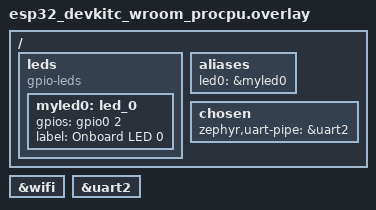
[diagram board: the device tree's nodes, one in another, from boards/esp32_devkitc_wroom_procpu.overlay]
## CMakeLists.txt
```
cmake_minimum_required(VERSION 3.13.1)
message("WORKSPACE_BASE = $ENV{WORKSPACE_BASE}")
message("ZEPHYR_BASE = $ENV{ZEPHYR_BASE}")
message("ZEPHYR_SDK_INSTALL_DIR = $ENV{ZEPHYR_SDK_INSTALL_DIR}")
message("ZEPHYR_TOOLCHAIN_VARIANT = $ENV{ZEPHYR_TOOLCHAIN_VARIANT}")

set(CONFIG_OUTPUT_DISASSEMBLY y CACHE INTERNAL "")
set(CONFIG_OUTPUT_DISASSEMBLY_WITH_SOURCE y CACHE INTERNAL "")

list(APPEND EXTRA_CONF_FILE
    ${CMAKE_CURRENT_SOURCE_DIR}/conf/kernel.conf
    ${CMAKE_CURRENT_SOURCE_DIR}/conf/net.conf
    ${CMAKE_CURRENT_SOURCE_DIR}/conf/modules.conf
    ${CMAKE_CURRENT_SOURCE_DIR}/conf/rpc.conf
    ${CMAKE_CURRENT_SOURCE_DIR}/conf/tracing.conf
    ${CMAKE_CURRENT_SOURCE_DIR}/conf/tracemodule.conf
)

# Which networking fragment to apply. Declare the type with
# CONFIG_APP_NET_TYPE_<X>=y in boards/<board>.conf (or prj.conf); the helper reads
# that declaration here, because CONFIG_* are not CMake variables until
# find_package(Zephyr) below has run Kconfig -- by which point EXTRA_CONF_FILE is
# already consumed. See the header of app_net_type.cmake.
#
# The "wifi" fallback must match the 'choice APP_NET_TYPE' default in Kconfig.
include($ENV{WORKSPACE_BASE}/common/scripts/cmake/app_net_type.cmake)
app_net_type_resolve(APP_NET_TYPE wifi)

if (APP_NET_TYPE STREQUAL "wifi")
    list(APPEND EXTRA_CONF_FILE ${CMAKE_CURRENT_SOURCE_DIR}/conf/nv.conf)
    list(APPEND EXTRA_CONF_FILE ${CMAKE_CURRENT_SOURCE_DIR}/conf/wifi.conf)
elseif (APP_NET_TYPE STREQUAL "serial")
    list(APPEND EXTRA_CONF_FILE ${CMAKE_CURRENT_SOURCE_DIR}/conf/serial_net.conf)
elseif (APP_NET_TYPE STREQUAL "eth")
    list(APPEND EXTRA_CONF_FILE ${CMAKE_CURRENT_SOURCE_DIR}/conf/wired_eth_net.conf)
endif()

find_package(Zephyr REQUIRED HINTS $ENV{ZEPHYR_BASE})

# Kconfig has now run. Fail loudly if it disagrees with the fragment we applied.
app_net_type_verify(${APP_NET_TYPE})

project(rpc_demo)


set(target app)

# Include the cmake script which builds protobuf bindings.
include($ENV{WORKSPACE_BASE}/common/scripts/cmake/build_proto.cmake)

# The following creates the target ${target}_proto.
nanopb_build_sources(${target} $ENV{WORKSPACE_BASE}/proto)

target_sources(
    ${target}
    PRIVATE
    src/main.c
    src/rpc.c
    )

target_sources_ifdef(
    CONFIG_APP_NET_TYPE_ETH
    ${target}
    PRIVATE 
    src/wired_net.c
    )

target_sources_ifdef(
    CONFIG_TRACERAM
    ${target}
    PRIVATE 
    $ENV{WORKSPACE_BASE}/common/modules/TraceRam/src/TraceRam_backend.c
    )

target_compile_options(
    ${target}
    PUBLIC
    -fmax-errors=5
    )

target_link_libraries(
    ${target}
    INTERFACE
    ${target}_proto
    )
```

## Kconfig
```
mainmenu "rpc demo application"

menu "App Options"

	choice APP_NET_TYPE
		prompt "Network type"
		default APP_NET_TYPE_WIFI

		config APP_NET_TYPE_WIFI
		bool "wifi network"

		config APP_NET_TYPE_SERIAL
		bool "serial net"

		config APP_NET_TYPE_ETH
		bool "wired ethernet networking"
	endchoice

	config APP_USE_STATIC_IP
	    bool "Use static ip."

	config APP_IPV4_ADDR
	    string "IP address for the serial interface."
	    default "192.0.2.1"

	config APP_IPV4_MASK
	    string "IP netmask for the serial interface."
	    default "255.255.255.0"

	config APP_IPV4_GW
	    string "IP gateway for the serial interface."
	    default "192.0.2.2"

endmenu

source "Kconfig.zephyr"

module = APP
module-str = "app"
source "subsys/logging/Kconfig.template.log_config"
```

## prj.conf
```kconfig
CONFIG_MAIN_STACK_SIZE=1024

CONFIG_APP_USE_STATIC_IP=y
CONFIG_APP_IPV4_ADDR="192.168.1.15"
CONFIG_APP_IPV4_MASK="255.255.255.0"
CONFIG_APP_IPV4_GW="192.168.1.1"

CONFIG_NET_DHCPV4=n

CONFIG_APP_LOG_LEVEL_INF=y
CONFIG_LOG_BUFFER_SIZE=1024
CONFIG_SHELL_BACKEND_SERIAL_LOG_MESSAGE_QUEUE_SIZE=1024
```

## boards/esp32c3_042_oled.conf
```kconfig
# Warning: Asserts in esp_heap_runtime_init do not print to console.
# Apparently setting the HEAP_MEM_POOL_SIZE impacts how much heap is seen by ESP_HEAP_RUNTIME_MAX_SIZE.
# If CONFIG_HEAP_MEM_POOL_SIZE is too large and WIFI or BT is enabled, the asserts will trip with no console message.
# Heap size of 10000 seems to work.
CONFIG_HEAP_MEM_POOL_SIZE=10000
CONFIG_I2C=y
CONFIG_I2C_ESP32=y
CONFIG_I2C_SHELL=y
CONFIG_SENSOR=y
CONFIG_SENSOR_SHELL=y

CONFIG_WIFI_ESP32=y
CONFIG_ESP32_WIFI_STA_AUTO_DHCPV4=y
CONFIG_ESP32_WIFI_STA_RECONNECT=y
```

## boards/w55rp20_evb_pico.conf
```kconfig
# Network type for this board. This single declaration drives both the Kconfig
# symbol and which conf/ fragment the build applies (see CMakeLists.txt and
# common/scripts/cmake/app_net_type.cmake).
CONFIG_APP_NET_TYPE_ETH=y

# The board puts the console on USB CDC-ACM, so there is an interactive port
# available with no extra hardware. Enable the shell on it -- the app only logs
# during startup, which USB enumeration always misses, so without a prompt the
# port looks dead even when it is working.
CONFIG_SHELL=y
```

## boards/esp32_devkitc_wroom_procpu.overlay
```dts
/ {
	leds {
		compatible = "gpio-leds";
		myled0: led_0 {
			gpios = <&gpio0 2 GPIO_ACTIVE_HIGH>;
			label = "Onboard LED 0";
		};
	};


	aliases {
		led0 = &myled0;
	};

	chosen {
		zephyr,uart-pipe = &uart2;
	};
};

&wifi {
	status = "okay";
};

&uart2 {
	status = "okay";
};
```

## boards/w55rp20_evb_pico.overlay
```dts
/*
 * Console on UART0 (GP0/GP1) instead of the board default USB CDC-ACM.
 *
 * The board puts the console on its own USB-C CDC-ACM device so that a bare
 * board needs no extra hardware. That device is enumerated by the RP2040
 * itself, which has two costs while developing this app:
 *
 *   - it disappears on every reset, reflash and gdb halt, so the terminal has
 *     to be reopened each time; and
 *   - it enumerates long after boot, so the early log lines are always lost.
 *
 * UART0 is live from the first instruction and is driven by a separate device
 * (the Raspberry Pi Debug Probe's UART bridge, or any USB-TTL adapter), so the
 * terminal stays put across resets and shows the whole boot.
 *
 * Requires wiring, or this port is silent:
 *   probe U connector TX (orange) -> GP1  (UART0 RX)
 *                     GND (black) -> GND
 *                     RX  (yellow)-> GP0  (UART0 TX)
 *
 * uart0 is already status = "okay" with uart0_default pinctrl on GP0/GP1 in the
 * board dts, so only the chosen nodes need repointing. See
 * common/boards/wiznet/w55rp20_evb_pico/README.md.
 *
 * SPDX-License-Identifier: Apache-2.0
 */

/ {
	chosen {
		zephyr,console = &uart0;
		zephyr,shell-uart = &uart0;
	};
};
```

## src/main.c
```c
/** @brief This examples demonstrates: RPC over Wifi
*/
#include <zephyr/kernel.h>
#include <zephyr/device.h>
#include <zephyr/devicetree.h>
#include <zephyr/sys/reboot.h>
#include <zephyr/logging/log.h>
#include <zephyr/drivers/gpio.h>
#include <zephyr/net/net_if.h>
#include <zephyr/net/wifi_mgmt.h>
#include "SwTimer.h"
#include "rpc.h"

/** @brief Initialize the logging module. */
LOG_MODULE_REGISTER(app, LOG_LEVEL_DBG);

/******************************************************************************/
#if defined(CONFIG_APP_NET_TYPE_WIFI)
#include "NvParms.h"
#include "WifiConnect.h"

static void
wifi_error(void)
{
    LOG_ERR("Rebooting system.");
    sys_reboot(SYS_REBOOT_COLD);
}

static int
init_wifi(void)
{
    char ssid[32];
    char pass[32];
    int ret, pass_len;

    ret = NvParms_load("ssid", NVPARMS_TYPE_STRING, ssid, sizeof(ssid));
    if (ret <= 0)
    {
        LOG_ERR("Error getting ssid from NV: %d", ret);
        return -1;
    }

    pass_len = NvParms_load("pass", NVPARMS_TYPE_STRING, pass, sizeof(pass));
    if (pass_len <= 0)
    {
        LOG_ERR("Error getting pass from NV: %d", pass_len);
        return -1;
    }

    LOG_DBG("ssid=%s", ssid);
    LOG_DBG("password length=%d", pass_len);

    //WifiConnect_init();
    WifiConnect_connect(ssid, pass, wifi_error);
    return 0;
}
#endif

#if defined(CONFIG_APP_NET_TYPE_SERIAL)
#include <zephyr/net/net_config.h>
#include <zephyr/net/net_if.h>
#include <zephyr/net/net_mgmt.h>
#include <zephyr/net/net_event.h>
#include <zephyr/net/conn_mgr_monitor.h>

#define EVENT_MASK (NET_EVENT_L4_CONNECTED | \
                    NET_EVENT_L4_DISCONNECTED)

static struct net_mgmt_event_callback mgmt_cb;
static bool connected = false;

static K_SEM_DEFINE(l4_connected, 0, 1);

static void
init_ip(void)
{
    struct net_if *iface;
    struct net_if_addr *ifaddr;
    struct in_addr my_ipv4_addr;
    struct in_addr my_ipv4_mask;
    struct in_addr my_ipv4_gw;

    iface = net_if_get_default();

    LOG_INF("Setting IP address for iface:");
    LOG_INF("  addr: %s", CONFIG_APP_IPV4_ADDR);
    LOG_INF("  mask: %s", CONFIG_APP_IPV4_MASK);
    LOG_INF("  gw  : %s", CONFIG_APP_IPV4_GW);

    net_addr_pton(AF_INET, CONFIG_APP_IPV4_ADDR, &my_ipv4_addr);
    net_addr_pton(AF_INET, CONFIG_APP_IPV4_MASK, &my_ipv4_mask);
    net_addr_pton(AF_INET, CONFIG_APP_IPV4_GW, &my_ipv4_gw);

    ifaddr = net_if_ipv4_addr_add(iface, &my_ipv4_addr, NET_ADDR_MANUAL, 0);
    if (!ifaddr)
    {
        LOG_ERR("Error setting IP address");
        return;
    }

    net_if_ipv4_set_netmask_by_addr(iface, &my_ipv4_addr, &my_ipv4_mask);
    net_if_ipv4_set_gw(iface, &my_ipv4_gw);
}

static void
l4_event_handler(
    struct net_mgmt_event_callback *cb,
    uint32_t mgmt_event,
    struct net_if *iface)
{
    ARG_UNUSED(iface);
    ARG_UNUSED(cb);

    LOG_DBG("mgmt_event = 0x%08x (EVENT_MASK = 0x%08x).",
        mgmt_event, (unsigned int)EVENT_MASK);

    switch (mgmt_event)
    {
    case NET_EVENT_L4_CONNECTED:
        LOG_DBG("NET_EVENT_L4_CONNECTED");
        connected = true;
        k_sem_give(&l4_connected);
        break;
    case NET_EVENT_L4_DISCONNECTED:
        LOG_DBG("NET_EVENT_L4_DISCONNECTED");
        if (connected)
        {
            LOG_INF("Network disconnected event");
            connected = false;
        }
        LOG_DBG("Resetting sem.");
        k_sem_reset(&l4_connected);
        break;
    case NET_EVENT_L4_IPV4_CONNECTED:
        LOG_DBG("NET_EVENT_L4_IPV4_CONNECTED");
        break;
    case NET_EVENT_L4_IPV4_DISCONNECTED:
        LOG_DBG("NET_EVENT_L4_IPV4_DISCONNECTED");
        break;
    case NET_EVENT_L4_IPV6_CONNECTED:
        LOG_DBG("NET_EVENT_L4_IPV6_CONNECTED");
        break;
    case NET_EVENT_L4_IPV6_DISCONNECTED:
        LOG_DBG("NET_EVENT_L4_IPV6_DISCONNECTED");
        break;

    default:
        break;
    }

}

static int
network_init(void)
{
    int ret;

    if (!IS_ENABLED(CONFIG_NET_CONNECTION_MANAGER))
    {
        LOG_ERR("Must set CONFIG_NET_CONNECTION_MANAGER=y in Kconfig.");
        return -1;
    }

    net_mgmt_init_event_callback(&mgmt_cb, l4_event_handler, EVENT_MASK);
    net_mgmt_add_event_callback(&mgmt_cb);
    conn_mgr_mon_resend_status();

    init_ip();

    ret = net_config_init_app(NULL, "Initializing network");
    if (ret < 0)
    {
        LOG_ERR("Failed network init (%d)", ret);
        return ret;
    }

    LOG_INF("Waiting for network connection...");

    /* Wait for the connection. */
    k_sem_take(&l4_connected, K_FOREVER);

    LOG_INF("Network connected.");

    return 0;
}
#endif


#if defined(CONFIG_TRACERAM)
#include <ctf_top.h>
#include "TraceRam.h"
//
//static inline void user_0(uint32_t el)
//{
//    CTF_EVENT(CTF_LITERAL(uint8_t, 0x99), el);
//}
#endif

int main(void)
{
    int ret;
    SwTimer t;

    LOG_INF("RPC demo app.");

#if defined(CONFIG_APP_NET_TYPE_WIFI)
    ret = NvParms_init();
    if (ret < 0)
    {
        LOG_ERR("NvParms module init error : %d", ret);
        return 0;
    }
    init_wifi();
#endif

#if defined(CONFIG_APP_NET_TYPE_SERIAL)
    network_init();
#endif

    rpc_init();
    rpc_start_server();

#if defined(CONFIG_TRACERAM)
    LOG_INF("Enabling trace ram.");
    TraceRam_enable();
#endif

    while (1)
    {

        k_msleep(40000);
        // Force disconnect for testing.
        //struct net_if *iface = net_if_get_default();
        //net_mgmt(NET_REQUEST_WIFI_DISCONNECT, iface, NULL, 0);

        //#if defined(CONFIG_TRACERAM)
        //        user_0(el);
        //#endif

    }

    return 0;
}
```

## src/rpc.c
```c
/*******************************************************************************
 *  @file: rpc.c
 *  
 *  @brief: Declarations and init for rpc.
*******************************************************************************/
#include "TcpRpcServer.h"
#include "ProtoRpc.h"

#include <zephyr/logging/log.h>
LOG_MODULE_DECLARE(app, CONFIG_APP_LOG_LEVEL);

#include "TestRpc.h"
#include "TestRpc.pb.h"
#include "SystemRpc.h"
#include "SystemRpc.pb.h"
#include "RtosUtilsRpc.h"
#include "RtosUtilsRpc.pb.h"

static ProtoRpc_Callset_Entry callsets[] = {
    PROTORPC_ADD_CALLSET(0, SystemRpc_resolver, system_Callset),
    PROTORPC_ADD_CALLSET(1, RtosUtilsRpc_resolver, rtosutils_Callset),
};

static TcpRpcServer tcp_rpc;
static ProtoRpc rpc;

#define RPCSERVER_STACK_SIZE    4*1024
#define RPC_USE_STATIC  0

#if RPC_USE_STATIC == 0
static uint8_t *rpc_call_frame;
static uint8_t *rpc_reply_frame;
static uint8_t *rpc_callset_call_buf;
static uint8_t *rpc_callset_reply_buf;
#else
static uint8_t rpc_call_frame[1008];
static uint8_t rpc_reply_frame[1408];
static uint8_t rpc_callset_call_buf[1000];
static uint8_t rpc_callset_reply_buf[1408];
#endif

/******************************************************************************
    [docimport rpc_start_server]
*//**
    @brief Starts the RPC server thread.
******************************************************************************/
int
rpc_start_server(void)
{
    LOG_INF("Starting tcp rpc server on port %u.", CONFIG_TCPRPCSERVER_PORT);

    /* Start TCP Rcp server. */
    int ret = TcpRpcServer_init(
        &tcp_rpc,
        &rpc,
        CONFIG_TCPRPCSERVER_PORT,
        RPCSERVER_STACK_SIZE,
        20);
    if (ret < 0) LOG_ERR("Error initializing TcpRpcServer.");
    
    return ret;
}

/******************************************************************************
    [docimport rpc_init]
*//**
    @brief Performs rpc initializations.
******************************************************************************/
int
rpc_init(void)
{
    uint32_t k;
    uint32_t max_callset_size = 0;

    for (k = 0; k < PROTORPC_ARRAY_LENGTH(callsets); k++)
    {
        if (callsets[k].size > max_callset_size)
        {
            max_callset_size = callsets[k].size;
        }
    }

    LOG_DBG("Max rpc callset size: %u", max_callset_size);

#if RPC_USE_STATIC == 0
    rpc_call_frame = k_malloc(ProtoRpcHeader_size + max_callset_size);
    if (!rpc_call_frame)
    {
        LOG_ERR("Error allocating memory for rpc_call_frame.");
        return -ENOMEM;
    }

    rpc_reply_frame = k_malloc(ProtoRpcHeader_size + max_callset_size);
    if (!rpc_reply_frame)
    {
        LOG_ERR("Error allocating memory for rpc_reply_frame.");
        return -ENOMEM;
    }

    rpc_callset_call_buf = k_malloc(max_callset_size);
    if (!rpc_callset_call_buf)
    {
        LOG_ERR("Error allocating memory for rpc_callset_call_buf.");
        return -ENOMEM;
    }

    rpc_callset_reply_buf = k_malloc(max_callset_size);
    if (!rpc_callset_reply_buf)
    {
        LOG_ERR("Error allocating memory for rpc_callset_reply_buf.");
        return -ENOMEM;
    }
#endif

    /** @brief Init the rpc object. */
    rpc.call_frame             = rpc_call_frame;
    rpc.reply_frame            = rpc_reply_frame;
    rpc.callsets               = callsets;
    rpc.callset_call_buf       = rpc_callset_call_buf;
    rpc.callset_call_buf_size  = sizeof(rpc_callset_call_buf);
    rpc.callset_reply_buf      = rpc_callset_reply_buf;
    rpc.callset_reply_buf_size = sizeof(rpc_callset_reply_buf);
    rpc.num_callsets           = PROTORPC_ARRAY_LENGTH(callsets);

    return 0;
}
```

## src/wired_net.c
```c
#include <zephyr/kernel.h>
#include <zephyr/logging/log.h>
#include <zephyr/net/net_config.h>
#include <zephyr/net/net_if.h>
#include <zephyr/net/net_mgmt.h>
#include <zephyr/net/net_event.h>
#include <zephyr/net/conn_mgr_monitor.h>

LOG_MODULE_DECLARE(app, CONFIG_APP_LOG_LEVEL);

#define EVENT_MASK (NET_EVENT_L4_CONNECTED | \
                    NET_EVENT_L4_DISCONNECTED)

static struct net_mgmt_event_callback mgmt_cb;
static bool connected = false;

static K_SEM_DEFINE(l4_connected, 0, 1);

static void
init_ip(void)
{
    struct net_if *iface;
    struct net_if_addr *ifaddr;
    struct in_addr my_ipv4_addr;
    struct in_addr my_ipv4_mask;
    struct in_addr my_ipv4_gw;

    iface = net_if_get_default();

    LOG_INF("Setting IP address for iface:");
    LOG_INF("  addr: %s", CONFIG_APP_IPV4_ADDR);
    LOG_INF("  mask: %s", CONFIG_APP_IPV4_MASK);
    LOG_INF("  gw  : %s", CONFIG_APP_IPV4_GW);

    net_addr_pton(AF_INET, CONFIG_APP_IPV4_ADDR, &my_ipv4_addr);
    net_addr_pton(AF_INET, CONFIG_APP_IPV4_MASK, &my_ipv4_mask);
    net_addr_pton(AF_INET, CONFIG_APP_IPV4_GW, &my_ipv4_gw);

    ifaddr = net_if_ipv4_addr_add(iface, &my_ipv4_addr, NET_ADDR_MANUAL, 0);
    if (!ifaddr)
    {
        LOG_ERR("Error setting IP address");
        return;
    }

    net_if_ipv4_set_netmask_by_addr(iface, &my_ipv4_addr, &my_ipv4_mask);
    net_if_ipv4_set_gw(iface, &my_ipv4_gw);
}

static void
l4_event_handler(
    struct net_mgmt_event_callback *cb,
    uint32_t mgmt_event,
    struct net_if *iface)
{
    ARG_UNUSED(iface);
    ARG_UNUSED(cb);

    LOG_DBG("mgmt_event = 0x%08x (EVENT_MASK = 0x%08x).",
        mgmt_event, (unsigned int)EVENT_MASK);

    switch (mgmt_event)
    {
    case NET_EVENT_L4_CONNECTED:
        LOG_INF("NET_EVENT_L4_CONNECTED");
        connected = true;
        k_sem_give(&l4_connected);
        break;
    case NET_EVENT_L4_DISCONNECTED:
        LOG_INF("NET_EVENT_L4_DISCONNECTED");
        if (connected)
        {
            LOG_INF("Network disconnected event");
            connected = false;
        }
        LOG_DBG("Resetting sem.");
        k_sem_reset(&l4_connected);
        break;
    case NET_EVENT_L4_IPV4_CONNECTED:
        LOG_INF("NET_EVENT_L4_IPV4_CONNECTED");
        break;
    case NET_EVENT_L4_IPV4_DISCONNECTED:
        LOG_INF("NET_EVENT_L4_IPV4_DISCONNECTED");
        break;
    case NET_EVENT_L4_IPV6_CONNECTED:
        LOG_INF("NET_EVENT_L4_IPV6_CONNECTED");
        break;
    case NET_EVENT_L4_IPV6_DISCONNECTED:
        LOG_INF("NET_EVENT_L4_IPV6_DISCONNECTED");
        break;

    default:
        break;
    }
}

int
network_init(void)
{
    int ret;

    if (!IS_ENABLED(CONFIG_NET_CONNECTION_MANAGER))
    {
        LOG_ERR("Must set CONFIG_NET_CONNECTION_MANAGER=y in Kconfig.");
        return -1;
    }

    net_mgmt_init_event_callback(&mgmt_cb, l4_event_handler, EVENT_MASK);
    net_mgmt_add_event_callback(&mgmt_cb);
    conn_mgr_mon_resend_status();

#if defined(CONFIG_APP_USE_STATIC_IP)
    init_ip();
#endif

    ret = net_config_init_app(NULL, "Initializing network");
    if (ret < 0)
    {
        LOG_ERR("Failed network init (%d)", ret);
        return ret;
    }

    LOG_INF("Waiting for network connection...");

    /* Wait for the connection. */
    k_sem_take(&l4_connected, K_FOREVER);

    LOG_INF("Network connected.");

    return 0;
}
```

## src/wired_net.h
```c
/* wired_net.h */
int network_init(void);
```
